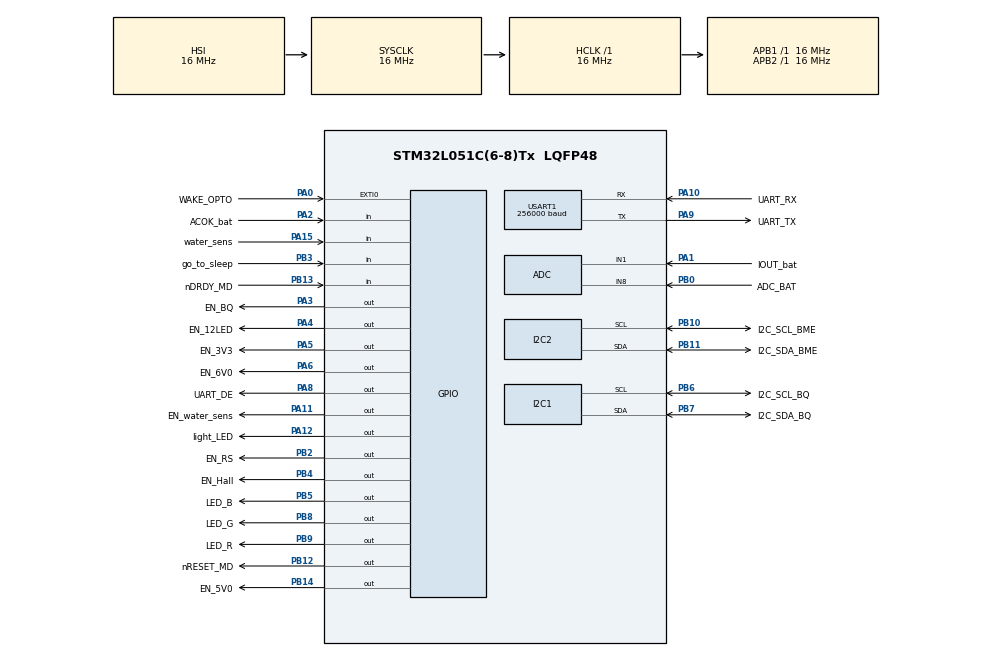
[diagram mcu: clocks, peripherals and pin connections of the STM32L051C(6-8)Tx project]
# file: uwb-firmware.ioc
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ADC.DiscontinuousConvMode=ENABLE
ADC.LowPowerAutoPowerOff=DISABLE
Dma.Request0=USART1_TX
Dma.USART1_TX.0.Direction=DMA_MEMORY_TO_PERIPH
Dma.USART1_TX.0.Instance=DMA1_Channel2
Dma.USART1_TX.0.MemDataAlignment=DMA_MDATAALIGN_BYTE
Dma.USART1_TX.0.MemInc=DMA_MINC_ENABLE
Dma.USART1_TX.0.Mode=DMA_NORMAL
Dma.USART1_TX.0.PeriphDataAlignment=DMA_PDATAALIGN_BYTE
Dma.USART1_TX.0.PeriphInc=DMA_PINC_DISABLE
Dma.USART1_TX.0.Priority=DMA_PRIORITY_LOW
I2C1.Timing=0x00303D5B
I2C2.Timing=0x00303D5B
Mcu.Family=STM32L0
Mcu.Name=STM32L051C(6-8)Tx
Mcu.Package=LQFP48
NVIC.DMA1_Channel2_3_IRQn=true\:0\:0\:false\:false\:true\:false\:true\:true
NVIC.EXTI0_1_IRQn=true\:0\:0\:false\:false\:true\:true\:true\:true
NVIC.TIM6_DAC_IRQn=true\:0\:0\:false\:false\:true\:true\:true\:true
NVIC.USART1_IRQn=true\:0\:0\:false\:false\:true\:true\:true\:true
PA0.GPIO_Label=WAKE_OPTO
PA0.GPIO_ModeDefaultEXTI=GPIO_MODE_IT_RISING
PA0.GPIO_PuPd=GPIO_PULLDOWN
PA0.Signal=GPXTI0
PA1.GPIO_Label=IOUT_bat
PA1.Mode=IN1
PA1.Signal=ADC_IN1
PA10.GPIO_Label=UART_RX
PA10.Mode=Asynchronous
PA10.Signal=USART1_RX
PA11.GPIO_Label=EN_water_sens
PA11.PinState=GPIO_PIN_SET
PA11.Signal=GPIO_Output
PA12.GPIO_Label=light_LED
PA12.Signal=GPIO_Output
PA15.GPIO_Label=water_sens
PA15.Signal=GPIO_Input
PA2.GPIO_Label=ACOK_bat
PA2.GPIO_PuPd=GPIO_PULLUP
PA2.Signal=GPIO_Input
PA3.GPIO_Label=EN_BQ
PA3.PinState=GPIO_PIN_RESET
PA3.Signal=GPIO_Output
PA4.GPIO_Label=EN_12LED
PA4.PinState=GPIO_PIN_RESET
PA4.Signal=GPIO_Output
PA5.GPIO_Label=EN_3V3
PA5.Signal=GPIO_Output
PA6.GPIO_Label=EN_6V0
PA6.Signal=GPIO_Output
PA8.GPIO_Label=UART_DE
PA8.Signal=GPIO_Output
PA9.GPIO_Label=UART_TX
PA9.Mode=Asynchronous
PA9.Signal=USART1_TX
PB0.GPIO_Label=ADC_BAT
PB0.Mode=IN8
PB0.Signal=ADC_IN8
PB10.GPIO_Label=I2C_SCL_BME
PB10.Mode=I2C
PB10.Signal=I2C2_SCL
PB11.GPIO_Label=I2C_SDA_BME
PB11.Mode=I2C
PB11.Signal=I2C2_SDA
PB12.GPIO_Label=nRESET_MD
PB12.Signal=GPIO_Output
PB13.GPIO_Label=nDRDY_MD
PB13.Signal=GPIO_Input
PB14.GPIO_Label=EN_5V0
PB14.Signal=GPIO_Output
PB2.GPIO_Label=EN_RS
PB2.PinState=GPIO_PIN_SET
PB2.Signal=GPIO_Output
PB3.GPIO_Label=go_to_sleep
PB3.Signal=GPIO_Input
PB4.GPIO_Label=EN_Hall
PB4.Signal=GPIO_Output
PB5.GPIO_Label=LED_B
PB5.Signal=GPIO_Output
PB6.GPIO_Label=I2C_SCL_BQ
PB6.Mode=I2C
PB6.Signal=I2C1_SCL
PB7.GPIO_Label=I2C_SDA_BQ
PB7.Mode=I2C
PB7.Signal=I2C1_SDA
PB8.GPIO_Label=LED_G
PB8.Signal=GPIO_Output
PB9.GPIO_Label=LED_R
PB9.Signal=GPIO_Output
ProjectManager.HeapSize=0x200
ProjectManager.StackSize=0x400
ProjectManager.TargetToolchain=STM32CubeIDE
RCC.AHBFreq_Value=16000000
RCC.APB1Freq_Value=16000000
RCC.APB1TimFreq_Value=16000000
RCC.APB2Freq_Value=16000000
RCC.APB2TimFreq_Value=16000000
RCC.HCLKFreq_Value=16000000
RCC.HSE_VALUE=8000000
RCC.HSI16_VALUE=16000000
RCC.HSI_VALUE=16000000
RCC.LSE_VALUE=32768
RCC.MSI_VALUE=2097000
RCC.SYSCLKFreq_VALUE=16000000
RCC.SYSCLKSource=RCC_SYSCLKSOURCE_HSI
RCC.VCOOutputFreq_Value=48000000
TIM6.Period=2500
TIM6.Prescaler=15
USART1.BaudRate=256000
USART1.VirtualMode-Asynchronous=VM_ASYNC
VP_TIM6_VS_ClockSourceINT.Mode=Enable_Timer
board=custom

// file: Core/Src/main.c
/* USER CODE BEGIN Header */
/**
  ******************************************************************************
  * @file           : main.c
  * @brief          : Main program body
  ******************************************************************************
  * @attention
  *
  * Copyright (c) 2022 STMicroelectronics.
  * All rights reserved.
  *
  * This software is licensed under terms that can be found in the LICENSE file
  * in the root directory of this software component.
  * If no LICENSE file comes with this software, it is provided AS-IS.
  *
  ******************************************************************************
  */
/* USER CODE END Header */
#include "main.h"
#include "adc.h"
#include "dma.h"
#include "i2c.h"
#include "tim.h"
#include "usart.h"
#include "gpio.h"

/* USER CODE BEGIN Includes */
#include "uwb.h"

/* USER CODE END Includes */

void SystemClock_Config(void);

int main(void)
{

  /* MCU Configuration--------------------------------------------------------*/

  /* Reset of all peripherals, Initializes the Flash interface and the Systick. */
  HAL_Init();

  /* Configure the system clock */
  SystemClock_Config();

  /* Initialize all configured peripherals */
  MX_GPIO_Init();
  MX_ADC_Init();
  MX_I2C1_Init();
  MX_I2C2_Init();
  MX_DMA_Init();
  MX_TIM6_Init();
  MX_USART1_UART_Init();
  /* USER CODE BEGIN 2 */

  uwb_init();

  /* USER CODE END 2 */

  /* Infinite loop */
  while (1)
  {

    /* USER CODE BEGIN 3 */

    uwb_handle();
  }
  /* USER CODE END 3 */
}

void SystemClock_Config(void)
{
  RCC_OscInitTypeDef RCC_OscInitStruct = {0};
  RCC_ClkInitTypeDef RCC_ClkInitStruct = {0};
  RCC_PeriphCLKInitTypeDef PeriphClkInit = {0};

  /** Configure the main internal regulator output voltage
  */
  __HAL_PWR_VOLTAGESCALING_CONFIG(PWR_REGULATOR_VOLTAGE_SCALE1);

  /** Initializes the RCC Oscillators according to the specified parameters
  * in the RCC_OscInitTypeDef structure.
  */
  RCC_OscInitStruct.OscillatorType = RCC_OSCILLATORTYPE_HSI;
  RCC_OscInitStruct.HSIState = RCC_HSI_ON;
  RCC_OscInitStruct.HSICalibrationValue = RCC_HSICALIBRATION_DEFAULT;
  RCC_OscInitStruct.PLL.PLLState = RCC_PLL_NONE;
  if (HAL_RCC_OscConfig(&RCC_OscInitStruct) != HAL_OK)
  {
    Error_Handler();
  }

  /** Initializes the CPU, AHB and APB buses clocks
  */
  RCC_ClkInitStruct.ClockType = RCC_CLOCKTYPE_HCLK|RCC_CLOCKTYPE_SYSCLK
                              |RCC_CLOCKTYPE_PCLK1|RCC_CLOCKTYPE_PCLK2;
  RCC_ClkInitStruct.SYSCLKSource = RCC_SYSCLKSOURCE_HSI;
  RCC_ClkInitStruct.AHBCLKDivider = RCC_SYSCLK_DIV1;
  RCC_ClkInitStruct.APB1CLKDivider = RCC_HCLK_DIV1;
  RCC_ClkInitStruct.APB2CLKDivider = RCC_HCLK_DIV1;

  if (HAL_RCC_ClockConfig(&RCC_ClkInitStruct, FLASH_LATENCY_0) != HAL_OK)
  {
    Error_Handler();
  }
  PeriphClkInit.PeriphClockSelection = RCC_PERIPHCLK_USART1|RCC_PERIPHCLK_I2C1;
  PeriphClkInit.Usart1ClockSelection = RCC_USART1CLKSOURCE_PCLK2;
  PeriphClkInit.I2c1ClockSelection = RCC_I2C1CLKSOURCE_PCLK1;
  if (HAL_RCCEx_PeriphCLKConfig(&PeriphClkInit) != HAL_OK)
  {
    Error_Handler();
  }
}

void Error_Handler(void)
{
  __disable_irq();
  while (1)
  {
  }
}
